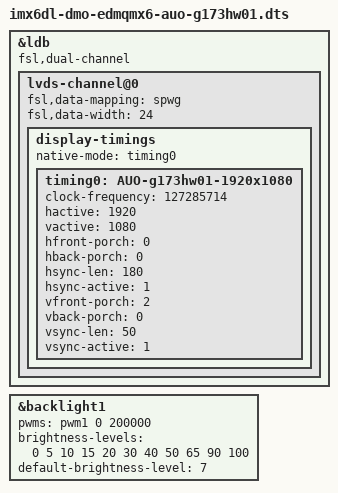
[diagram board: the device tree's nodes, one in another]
/*
 * Copyright 2011 Freescale Semiconductor, Inc.
 * Copyright 2011 Linaro Ltd.
 *
 * The code contained herein is licensed under the GNU General Public
 * License. You may obtain a copy of the GNU General Public License
 * Version 2 or later at the following locations:
 *
 * http://www.opensource.org/licenses/gpl-license.html
 * http://www.gnu.org/copyleft/gpl.html
 */

#include "imx6q-dmo-edmqmx6.dts"

&ldb {
	status = "okay";
	fsl,dual-channel;

	lvds-channel@0 {
		status = "okay";
		fsl,data-mapping = "spwg";
		fsl,data-width = <24>;

		display-timings {
			native-mode = <&timing0>;

			timing0: AUO-g173hw01-1920x1080 {
				clock-frequency = <127285714>;
				hactive = <1920>;
				vactive = <1080>;
				hfront-porch = <0>;
				hback-porch = <0>;
				hsync-len = <180>;
				hsync-active = <1>;
				vfront-porch = <2>;
				vback-porch = <0>;
				vsync-len = <50>;
				vsync-active = <1>;
			};
		};
	};
};

&backlight1 {
	pwms = <&pwm1 0 200000>;
	brightness-levels = <0 5 10 15 20 30 40 50 65 90 100>;
	default-brightness-level = <7>;
	status = "okay";
};
